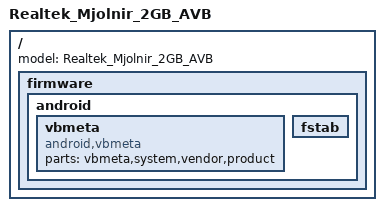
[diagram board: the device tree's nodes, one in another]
#include "rtd-1619-mjolnir-2GB.dts"
#include "rtd-16xx-avb.dtsi"

/ {
	model= "Realtek_Mjolnir_2GB_AVB";
	firmware {
		android {
			vbmeta {
				compatible = "android,vbmeta";
				parts = "vbmeta,system,vendor,product";
			};
			fstab {
				/delete-node/ system;
				/delete-node/ vendor;
				/delete-node/ product;
			};
		};
	};
};

